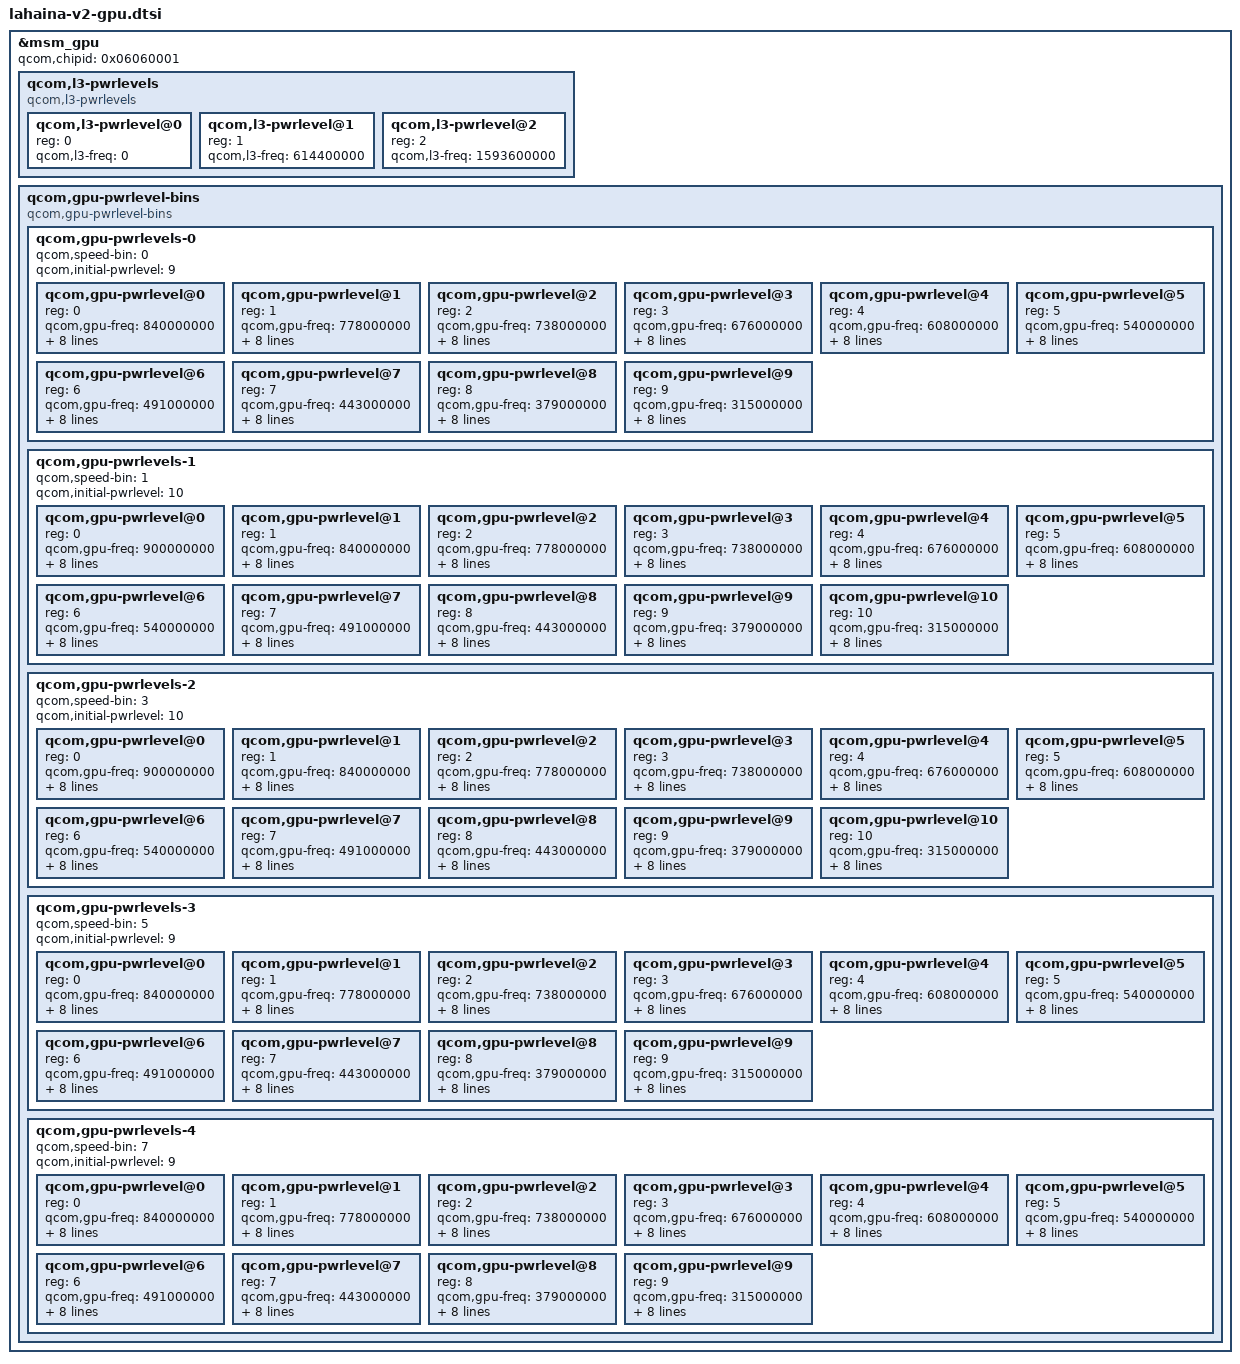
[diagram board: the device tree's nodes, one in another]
&msm_gpu {
	qcom,chipid = <0x06060001>;

	/delete-property/qcom,initial-pwrlevel;
	/delete-node/qcom,gpu-pwrlevels;

	qcom,l3-pwrlevels {
			#address-cells = <1>;
			#size-cells = <0>;

			compatible = "qcom,l3-pwrlevels";

			qcom,l3-pwrlevel@0 {
				reg = <0>;
				qcom,l3-freq = <0>;
			};

			qcom,l3-pwrlevel@1 {
				reg = <1>;
				qcom,l3-freq = <614400000>;
			};

			qcom,l3-pwrlevel@2 {
				reg = <2>;
				qcom,l3-freq = <1593600000>;
			};
		};

	/* Power levels bins */
	qcom,gpu-pwrlevel-bins {
		compatible="qcom,gpu-pwrlevel-bins";
		#address-cells = <1>;
		#size-cells = <0>;

		qcom,gpu-pwrlevels-0 {
			#address-cells = <1>;
			#size-cells = <0>;
			qcom,speed-bin = <0>;
			qcom,initial-pwrlevel = <9>;

			qcom,gpu-pwrlevel@0 {
				reg = <0>;
				qcom,gpu-freq = <840000000>;
				qcom,level = <RPMH_REGULATOR_LEVEL_TURBO_L1>;

				qcom,bus-freq-ddr7 = <11>;
				qcom,bus-min-ddr7 = <11>;
				qcom,bus-max-ddr7 = <11>;

				qcom,bus-freq-ddr8 = <11>;
				qcom,bus-min-ddr8 = <11>;
				qcom,bus-max-ddr8 = <11>;

				qcom,acd-level = <0x882a5ffd>;
			};

			qcom,gpu-pwrlevel@1 {
				reg = <1>;
				qcom,gpu-freq = <778000000>;
				qcom,level = <RPMH_REGULATOR_LEVEL_TURBO>;

				qcom,bus-freq-ddr7 = <11>;
				qcom,bus-min-ddr7 = <11>;
				qcom,bus-max-ddr7 = <11>;

				qcom,bus-freq-ddr8 = <11>;
				qcom,bus-min-ddr8 = <11>;
				qcom,bus-max-ddr8 = <11>;

				qcom,acd-level = <0xa82a5ffd>;
			};

			qcom,gpu-pwrlevel@2 {
				reg = <2>;
				qcom,gpu-freq = <738000000>;
				qcom,level = <RPMH_REGULATOR_LEVEL_NOM_L1>;

				qcom,bus-freq-ddr7 = <11>;
				qcom,bus-min-ddr7 = <11>;
				qcom,bus-max-ddr7 = <11>;

				qcom,bus-freq-ddr8 = <11>;
				qcom,bus-min-ddr8 = <11>;
				qcom,bus-max-ddr8 = <11>;

				qcom,acd-level = <0xa82a5ffd>;
			};

			qcom,gpu-pwrlevel@3 {
				reg = <3>;
				qcom,gpu-freq = <676000000>;
				qcom,level = <RPMH_REGULATOR_LEVEL_NOM>;

				qcom,bus-freq-ddr7 = <11>;
				qcom,bus-min-ddr7 = <11>;
				qcom,bus-max-ddr7 = <11>;

				qcom,bus-freq-ddr8 = <10>;
				qcom,bus-min-ddr8 = <10>;
				qcom,bus-max-ddr8 = <11>;

				qcom,acd-level = <0x882b5ffd>;
			};

			qcom,gpu-pwrlevel@4 {
				reg = <4>;
				qcom,gpu-freq = <608000000>;
				qcom,level = <RPMH_REGULATOR_LEVEL_SVS_L2>;

				qcom,bus-freq-ddr7 = <8>;
				qcom,bus-min-ddr7 = <7>;
				qcom,bus-max-ddr7 = <11>;

				qcom,bus-freq-ddr8 = <7>;
				qcom,bus-min-ddr8 = <7>;
				qcom,bus-max-ddr8 = <11>;

				qcom,acd-level = <0xa82b5ffd>;
			};

			qcom,gpu-pwrlevel@5 {
				reg = <5>;
				qcom,gpu-freq = <540000000>;
				qcom,level = <RPMH_REGULATOR_LEVEL_SVS_L1>;

				qcom,bus-freq-ddr7 = <8>;
				qcom,bus-min-ddr7 = <7>;
				qcom,bus-max-ddr7 = <10>;

				qcom,bus-freq-ddr8 = <7>;
				qcom,bus-min-ddr8 = <7>;
				qcom,bus-max-ddr8 = <9>;

				qcom,acd-level = <0xa82c5ffd>;
			};

			qcom,gpu-pwrlevel@6 {
				reg = <6>;
				qcom,gpu-freq = <491000000>;
				qcom,level = <RPMH_REGULATOR_LEVEL_SVS_L0>;

				qcom,bus-freq-ddr7 = <8>;
				qcom,bus-min-ddr7 = <6>;
				qcom,bus-max-ddr7 = <10>;

				qcom,bus-freq-ddr8 = <7>;
				qcom,bus-min-ddr8 = <5>;
				qcom,bus-max-ddr8 = <7>;

				qcom,acd-level = <0xa82c5ffd>;
			};

			qcom,gpu-pwrlevel@7 {
				reg = <7>;
				qcom,gpu-freq = <443000000>;
				qcom,level = <RPMH_REGULATOR_LEVEL_SVS>;

				qcom,bus-freq-ddr7 = <8>;
				qcom,bus-min-ddr7 = <6>;
				qcom,bus-max-ddr7 = <10>;

				qcom,bus-freq-ddr8 = <7>;
				qcom,bus-min-ddr8 = <5>;
				qcom,bus-max-ddr8 = <7>;

				qcom,acd-level = <0xa82d5ffd>;
			};

			qcom,gpu-pwrlevel@8 {
				reg = <8>;
				qcom,gpu-freq = <379000000>;
				qcom,level = <RPMH_REGULATOR_LEVEL_LOW_SVS_L1>;

				qcom,bus-freq-ddr7 = <8>;
				qcom,bus-min-ddr7 = <6>;
				qcom,bus-max-ddr7 = <10>;

				qcom,bus-freq-ddr8 = <6>;
				qcom,bus-min-ddr8 = <5>;
				qcom,bus-max-ddr8 = <7>;

				qcom,acd-level = <0x882e5ffd>;
			};

			qcom,gpu-pwrlevel@9 {
				reg = <9>;
				qcom,gpu-freq = <315000000>;
				qcom,level = <RPMH_REGULATOR_LEVEL_LOW_SVS>;

				qcom,bus-freq-ddr7 = <2>;
				qcom,bus-min-ddr7 = <2>;
				qcom,bus-max-ddr7 = <9>;

				qcom,bus-freq-ddr8 = <2>;
				qcom,bus-min-ddr8 = <2>;
				qcom,bus-max-ddr8 = <7>;

				qcom,acd-level = <0x882f5ffd>;
			};

		};

		qcom,gpu-pwrlevels-1 {
			#address-cells = <1>;
			#size-cells = <0>;
			qcom,speed-bin = <1>;
			qcom,initial-pwrlevel = <10>;

			qcom,gpu-pwrlevel@0 {
				reg = <0>;
				qcom,gpu-freq = <900000000>;
				qcom,level = <RPMH_REGULATOR_LEVEL_TURBO_L2>;

				qcom,bus-freq-ddr7 = <11>;
				qcom,bus-min-ddr7 = <11>;
				qcom,bus-max-ddr7 = <11>;

				qcom,bus-freq-ddr8 = <11>;
				qcom,bus-min-ddr8 = <11>;
				qcom,bus-max-ddr8 = <11>;

				qcom,acd-level = <0x882a5ffd>;
			};

			qcom,gpu-pwrlevel@1 {
				reg = <1>;
				qcom,gpu-freq = <840000000>;
				qcom,level = <RPMH_REGULATOR_LEVEL_TURBO_L1>;

				qcom,bus-freq-ddr7 = <11>;
				qcom,bus-min-ddr7 = <11>;
				qcom,bus-max-ddr7 = <11>;

				qcom,bus-freq-ddr8 = <11>;
				qcom,bus-min-ddr8 = <11>;
				qcom,bus-max-ddr8 = <11>;

				qcom,acd-level = <0x882a5ffd>;
			};

			qcom,gpu-pwrlevel@2 {
				reg = <2>;
				qcom,gpu-freq = <778000000>;
				qcom,level = <RPMH_REGULATOR_LEVEL_TURBO>;

				qcom,bus-freq-ddr7 = <11>;
				qcom,bus-min-ddr7 = <11>;
				qcom,bus-max-ddr7 = <11>;

				qcom,bus-freq-ddr8 = <11>;
				qcom,bus-min-ddr8 = <11>;
				qcom,bus-max-ddr8 = <11>;

				qcom,acd-level = <0xa82a5ffd>;
			};

			qcom,gpu-pwrlevel@3 {
				reg = <3>;
				qcom,gpu-freq = <738000000>;
				qcom,level = <RPMH_REGULATOR_LEVEL_NOM_L1>;

				qcom,bus-freq-ddr7 = <11>;
				qcom,bus-min-ddr7 = <11>;
				qcom,bus-max-ddr7 = <11>;

				qcom,bus-freq-ddr8 = <11>;
				qcom,bus-min-ddr8 = <11>;
				qcom,bus-max-ddr8 = <11>;

				qcom,acd-level = <0xa82a5ffd>;
			};

			qcom,gpu-pwrlevel@4 {
				reg = <4>;
				qcom,gpu-freq = <676000000>;
				qcom,level = <RPMH_REGULATOR_LEVEL_NOM>;

				qcom,bus-freq-ddr7 = <11>;
				qcom,bus-min-ddr7 = <11>;
				qcom,bus-max-ddr7 = <11>;

				qcom,bus-freq-ddr8 = <10>;
				qcom,bus-min-ddr8 = <10>;
				qcom,bus-max-ddr8 = <11>;

				qcom,acd-level = <0x882b5ffd>;
			};

			qcom,gpu-pwrlevel@5 {
				reg = <5>;
				qcom,gpu-freq = <608000000>;
				qcom,level = <RPMH_REGULATOR_LEVEL_SVS_L2>;

				qcom,bus-freq-ddr7 = <8>;
				qcom,bus-min-ddr7 = <7>;
				qcom,bus-max-ddr7 = <11>;

				qcom,bus-freq-ddr8 = <7>;
				qcom,bus-min-ddr8 = <7>;
				qcom,bus-max-ddr8 = <11>;

				qcom,acd-level = <0xa82b5ffd>;
			};

			qcom,gpu-pwrlevel@6 {
				reg = <6>;
				qcom,gpu-freq = <540000000>;
				qcom,level = <RPMH_REGULATOR_LEVEL_SVS_L1>;

				qcom,bus-freq-ddr7 = <8>;
				qcom,bus-min-ddr7 = <7>;
				qcom,bus-max-ddr7 = <10>;

				qcom,bus-freq-ddr8 = <7>;
				qcom,bus-min-ddr8 = <7>;
				qcom,bus-max-ddr8 = <9>;

				qcom,acd-level = <0xa82c5ffd>;
			};

			qcom,gpu-pwrlevel@7 {
				reg = <7>;
				qcom,gpu-freq = <491000000>;
				qcom,level = <RPMH_REGULATOR_LEVEL_SVS_L0>;

				qcom,bus-freq-ddr7 = <8>;
				qcom,bus-min-ddr7 = <6>;
				qcom,bus-max-ddr7 = <10>;

				qcom,bus-freq-ddr8 = <7>;
				qcom,bus-min-ddr8 = <5>;
				qcom,bus-max-ddr8 = <7>;

				qcom,acd-level = <0xa82c5ffd>;
			};

			qcom,gpu-pwrlevel@8 {
				reg = <8>;
				qcom,gpu-freq = <443000000>;
				qcom,level = <RPMH_REGULATOR_LEVEL_SVS>;

				qcom,bus-freq-ddr7 = <8>;
				qcom,bus-min-ddr7 = <6>;
				qcom,bus-max-ddr7 = <10>;

				qcom,bus-freq-ddr8 = <7>;
				qcom,bus-min-ddr8 = <5>;
				qcom,bus-max-ddr8 = <7>;

				qcom,acd-level = <0xa82d5ffd>;
			};

			qcom,gpu-pwrlevel@9 {
				reg = <9>;
				qcom,gpu-freq = <379000000>;
				qcom,level = <RPMH_REGULATOR_LEVEL_LOW_SVS_L1>;

				qcom,bus-freq-ddr7 = <8>;
				qcom,bus-min-ddr7 = <6>;
				qcom,bus-max-ddr7 = <10>;

				qcom,bus-freq-ddr8 = <6>;
				qcom,bus-min-ddr8 = <5>;
				qcom,bus-max-ddr8 = <7>;

				qcom,acd-level = <0x882e5ffd>;
			};

			qcom,gpu-pwrlevel@10 {
				reg = <10>;
				qcom,gpu-freq = <315000000>;
				qcom,level = <RPMH_REGULATOR_LEVEL_LOW_SVS>;

				qcom,bus-freq-ddr7 = <2>;
				qcom,bus-min-ddr7 = <2>;
				qcom,bus-max-ddr7 = <9>;

				qcom,bus-freq-ddr8 = <2>;
				qcom,bus-min-ddr8 = <2>;
				qcom,bus-max-ddr8 = <7>;

				qcom,acd-level = <0x882f5ffd>;
			};
		};

		qcom,gpu-pwrlevels-2 {
			#address-cells = <1>;
			#size-cells = <0>;
			qcom,speed-bin = <3>;
			qcom,initial-pwrlevel = <10>;

			qcom,gpu-pwrlevel@0 {
				reg = <0>;
				qcom,gpu-freq = <900000000>;
				qcom,level = <RPMH_REGULATOR_LEVEL_TURBO_L2>;

				qcom,bus-freq-ddr7 = <11>;
				qcom,bus-min-ddr7 = <11>;
				qcom,bus-max-ddr7 = <11>;

				qcom,bus-freq-ddr8 = <11>;
				qcom,bus-min-ddr8 = <11>;
				qcom,bus-max-ddr8 = <11>;

				qcom,acd-level = <0x882a5ffd>;
			};

			qcom,gpu-pwrlevel@1 {
				reg = <1>;
				qcom,gpu-freq = <840000000>;
				qcom,level = <RPMH_REGULATOR_LEVEL_TURBO_L1>;

				qcom,bus-freq-ddr7 = <11>;
				qcom,bus-min-ddr7 = <11>;
				qcom,bus-max-ddr7 = <11>;

				qcom,bus-freq-ddr8 = <11>;
				qcom,bus-min-ddr8 = <11>;
				qcom,bus-max-ddr8 = <11>;

				qcom,acd-level = <0x882a5ffd>;
			};

			qcom,gpu-pwrlevel@2 {
				reg = <2>;
				qcom,gpu-freq = <778000000>;
				qcom,level = <RPMH_REGULATOR_LEVEL_TURBO>;

				qcom,bus-freq-ddr7 = <11>;
				qcom,bus-min-ddr7 = <11>;
				qcom,bus-max-ddr7 = <11>;

				qcom,bus-freq-ddr8 = <11>;
				qcom,bus-min-ddr8 = <11>;
				qcom,bus-max-ddr8 = <11>;

				qcom,acd-level = <0xa82a5ffd>;
			};

			qcom,gpu-pwrlevel@3 {
				reg = <3>;
				qcom,gpu-freq = <738000000>;
				qcom,level = <RPMH_REGULATOR_LEVEL_NOM_L1>;

				qcom,bus-freq-ddr7 = <11>;
				qcom,bus-min-ddr7 = <11>;
				qcom,bus-max-ddr7 = <11>;

				qcom,bus-freq-ddr8 = <11>;
				qcom,bus-min-ddr8 = <11>;
				qcom,bus-max-ddr8 = <11>;

				qcom,acd-level = <0xa82a5ffd>;
			};

			qcom,gpu-pwrlevel@4 {
				reg = <4>;
				qcom,gpu-freq = <676000000>;
				qcom,level = <RPMH_REGULATOR_LEVEL_NOM>;

				qcom,bus-freq-ddr7 = <11>;
				qcom,bus-min-ddr7 = <11>;
				qcom,bus-max-ddr7 = <11>;

				qcom,bus-freq-ddr8 = <10>;
				qcom,bus-min-ddr8 = <10>;
				qcom,bus-max-ddr8 = <11>;

				qcom,acd-level = <0x882b5ffd>;
			};

			qcom,gpu-pwrlevel@5 {
				reg = <5>;
				qcom,gpu-freq = <608000000>;
				qcom,level = <RPMH_REGULATOR_LEVEL_SVS_L2>;

				qcom,bus-freq-ddr7 = <8>;
				qcom,bus-min-ddr7 = <7>;
				qcom,bus-max-ddr7 = <11>;

				qcom,bus-freq-ddr8 = <7>;
				qcom,bus-min-ddr8 = <7>;
				qcom,bus-max-ddr8 = <11>;

				qcom,acd-level = <0xa82b5ffd>;
			};

			qcom,gpu-pwrlevel@6 {
				reg = <6>;
				qcom,gpu-freq = <540000000>;
				qcom,level = <RPMH_REGULATOR_LEVEL_SVS_L1>;

				qcom,bus-freq-ddr7 = <8>;
				qcom,bus-min-ddr7 = <7>;
				qcom,bus-max-ddr7 = <10>;

				qcom,bus-freq-ddr8 = <7>;
				qcom,bus-min-ddr8 = <7>;
				qcom,bus-max-ddr8 = <9>;

				qcom,acd-level = <0xa82c5ffd>;
			};

			qcom,gpu-pwrlevel@7 {
				reg = <7>;
				qcom,gpu-freq = <491000000>;
				qcom,level = <RPMH_REGULATOR_LEVEL_SVS_L0>;

				qcom,bus-freq-ddr7 = <8>;
				qcom,bus-min-ddr7 = <6>;
				qcom,bus-max-ddr7 = <10>;

				qcom,bus-freq-ddr8 = <7>;
				qcom,bus-min-ddr8 = <5>;
				qcom,bus-max-ddr8 = <7>;

				qcom,acd-level = <0xa82c5ffd>;
			};

			qcom,gpu-pwrlevel@8 {
				reg = <8>;
				qcom,gpu-freq = <443000000>;
				qcom,level = <RPMH_REGULATOR_LEVEL_SVS>;

				qcom,bus-freq-ddr7 = <8>;
				qcom,bus-min-ddr7 = <6>;
				qcom,bus-max-ddr7 = <10>;

				qcom,bus-freq-ddr8 = <7>;
				qcom,bus-min-ddr8 = <5>;
				qcom,bus-max-ddr8 = <7>;

				qcom,acd-level = <0xa82d5ffd>;
			};

			qcom,gpu-pwrlevel@9 {
				reg = <9>;
				qcom,gpu-freq = <379000000>;
				qcom,level = <RPMH_REGULATOR_LEVEL_LOW_SVS_L1>;

				qcom,bus-freq-ddr7 = <8>;
				qcom,bus-min-ddr7 = <6>;
				qcom,bus-max-ddr7 = <10>;

				qcom,bus-freq-ddr8 = <6>;
				qcom,bus-min-ddr8 = <5>;
				qcom,bus-max-ddr8 = <7>;

				qcom,acd-level = <0x882e5ffd>;
			};

			qcom,gpu-pwrlevel@10 {
				reg = <10>;
				qcom,gpu-freq = <315000000>;
				qcom,level = <RPMH_REGULATOR_LEVEL_LOW_SVS>;

				qcom,bus-freq-ddr7 = <2>;
				qcom,bus-min-ddr7 = <2>;
				qcom,bus-max-ddr7 = <9>;

				qcom,bus-freq-ddr8 = <2>;
				qcom,bus-min-ddr8 = <2>;
				qcom,bus-max-ddr8 = <7>;

				qcom,acd-level = <0x882f5ffd>;
			};
		};

		qcom,gpu-pwrlevels-3 {
			#address-cells = <1>;
			#size-cells = <0>;
			qcom,speed-bin = <5>;
			qcom,initial-pwrlevel = <9>;

			qcom,gpu-pwrlevel@0 {
				reg = <0>;
				qcom,gpu-freq = <840000000>;
				qcom,level = <RPMH_REGULATOR_LEVEL_TURBO_L1>;

				qcom,bus-freq-ddr7 = <11>;
				qcom,bus-min-ddr7 = <11>;
				qcom,bus-max-ddr7 = <11>;

				qcom,bus-freq-ddr8 = <11>;
				qcom,bus-min-ddr8 = <11>;
				qcom,bus-max-ddr8 = <11>;

				qcom,acd-level = <0x882a5ffd>;
			};

			qcom,gpu-pwrlevel@1 {
				reg = <1>;
				qcom,gpu-freq = <778000000>;
				qcom,level = <RPMH_REGULATOR_LEVEL_TURBO>;

				qcom,bus-freq-ddr7 = <11>;
				qcom,bus-min-ddr7 = <11>;
				qcom,bus-max-ddr7 = <11>;

				qcom,bus-freq-ddr8 = <11>;
				qcom,bus-min-ddr8 = <11>;
				qcom,bus-max-ddr8 = <11>;

				qcom,acd-level = <0xa82a5ffd>;
			};

			qcom,gpu-pwrlevel@2 {
				reg = <2>;
				qcom,gpu-freq = <738000000>;
				qcom,level = <RPMH_REGULATOR_LEVEL_NOM_L1>;

				qcom,bus-freq-ddr7 = <11>;
				qcom,bus-min-ddr7 = <11>;
				qcom,bus-max-ddr7 = <11>;

				qcom,bus-freq-ddr8 = <11>;
				qcom,bus-min-ddr8 = <11>;
				qcom,bus-max-ddr8 = <11>;

				qcom,acd-level = <0xa82a5ffd>;
			};

			qcom,gpu-pwrlevel@3 {
				reg = <3>;
				qcom,gpu-freq = <676000000>;
				qcom,level = <RPMH_REGULATOR_LEVEL_NOM>;

				qcom,bus-freq-ddr7 = <11>;
				qcom,bus-min-ddr7 = <11>;
				qcom,bus-max-ddr7 = <11>;

				qcom,bus-freq-ddr8 = <10>;
				qcom,bus-min-ddr8 = <10>;
				qcom,bus-max-ddr8 = <11>;

				qcom,acd-level = <0x882b5ffd>;
			};

			qcom,gpu-pwrlevel@4 {
				reg = <4>;
				qcom,gpu-freq = <608000000>;
				qcom,level = <RPMH_REGULATOR_LEVEL_SVS_L2>;

				qcom,bus-freq-ddr7 = <8>;
				qcom,bus-min-ddr7 = <7>;
				qcom,bus-max-ddr7 = <11>;

				qcom,bus-freq-ddr8 = <7>;
				qcom,bus-min-ddr8 = <7>;
				qcom,bus-max-ddr8 = <11>;

				qcom,acd-level = <0xa82b5ffd>;
			};

			qcom,gpu-pwrlevel@5 {
				reg = <5>;
				qcom,gpu-freq = <540000000>;
				qcom,level = <RPMH_REGULATOR_LEVEL_SVS_L1>;

				qcom,bus-freq-ddr7 = <8>;
				qcom,bus-min-ddr7 = <7>;
				qcom,bus-max-ddr7 = <10>;

				qcom,bus-freq-ddr8 = <7>;
				qcom,bus-min-ddr8 = <7>;
				qcom,bus-max-ddr8 = <9>;

				qcom,acd-level = <0xa82c5ffd>;
			};

			qcom,gpu-pwrlevel@6 {
				reg = <6>;
				qcom,gpu-freq = <491000000>;
				qcom,level = <RPMH_REGULATOR_LEVEL_SVS_L0>;

				qcom,bus-freq-ddr7 = <8>;
				qcom,bus-min-ddr7 = <6>;
				qcom,bus-max-ddr7 = <10>;

				qcom,bus-freq-ddr8 = <7>;
				qcom,bus-min-ddr8 = <5>;
				qcom,bus-max-ddr8 = <7>;

				qcom,acd-level = <0xa82c5ffd>;
			};

			qcom,gpu-pwrlevel@7 {
				reg = <7>;
				qcom,gpu-freq = <443000000>;
				qcom,level = <RPMH_REGULATOR_LEVEL_SVS>;

				qcom,bus-freq-ddr7 = <8>;
				qcom,bus-min-ddr7 = <6>;
				qcom,bus-max-ddr7 = <10>;

				qcom,bus-freq-ddr8 = <7>;
				qcom,bus-min-ddr8 = <5>;
				qcom,bus-max-ddr8 = <7>;

				qcom,acd-level = <0xa82d5ffd>;
			};

			qcom,gpu-pwrlevel@8 {
				reg = <8>;
				qcom,gpu-freq = <379000000>;
				qcom,level = <RPMH_REGULATOR_LEVEL_LOW_SVS_L1>;

				qcom,bus-freq-ddr7 = <8>;
				qcom,bus-min-ddr7 = <6>;
				qcom,bus-max-ddr7 = <10>;

				qcom,bus-freq-ddr8 = <6>;
				qcom,bus-min-ddr8 = <5>;
				qcom,bus-max-ddr8 = <7>;

				qcom,acd-level = <0x882e5ffd>;
			};

			qcom,gpu-pwrlevel@9 {
				reg = <9>;
				qcom,gpu-freq = <315000000>;
				qcom,level = <RPMH_REGULATOR_LEVEL_LOW_SVS>;

				qcom,bus-freq-ddr7 = <2>;
				qcom,bus-min-ddr7 = <2>;
				qcom,bus-max-ddr7 = <9>;

				qcom,bus-freq-ddr8 = <2>;
				qcom,bus-min-ddr8 = <2>;
				qcom,bus-max-ddr8 = <7>;

				qcom,acd-level = <0x882f5ffd>;
			};
		};

		qcom,gpu-pwrlevels-4 {
			#address-cells = <1>;
			#size-cells = <0>;
			qcom,speed-bin = <7>;
			qcom,initial-pwrlevel = <9>;

			qcom,gpu-pwrlevel@0 {
				reg = <0>;
				qcom,gpu-freq = <840000000>;
				qcom,level = <RPMH_REGULATOR_LEVEL_TURBO_L1>;

				qcom,bus-freq-ddr7 = <11>;
				qcom,bus-min-ddr7 = <11>;
				qcom,bus-max-ddr7 = <11>;

				qcom,bus-freq-ddr8 = <11>;
				qcom,bus-min-ddr8 = <11>;
				qcom,bus-max-ddr8 = <11>;

				qcom,acd-level = <0x882a5ffd>;
			};

			qcom,gpu-pwrlevel@1 {
				reg = <1>;
				qcom,gpu-freq = <778000000>;
				qcom,level = <RPMH_REGULATOR_LEVEL_TURBO>;

				qcom,bus-freq-ddr7 = <11>;
				qcom,bus-min-ddr7 = <11>;
				qcom,bus-max-ddr7 = <11>;

				qcom,bus-freq-ddr8 = <11>;
				qcom,bus-min-ddr8 = <11>;
				qcom,bus-max-ddr8 = <11>;

				qcom,acd-level = <0xa82a5ffd>;
			};

			qcom,gpu-pwrlevel@2 {
				reg = <2>;
				qcom,gpu-freq = <738000000>;
				qcom,level = <RPMH_REGULATOR_LEVEL_NOM_L1>;

				qcom,bus-freq-ddr7 = <11>;
				qcom,bus-min-ddr7 = <11>;
				qcom,bus-max-ddr7 = <11>;

				qcom,bus-freq-ddr8 = <11>;
				qcom,bus-min-ddr8 = <11>;
				qcom,bus-max-ddr8 = <11>;

				qcom,acd-level = <0xa82a5ffd>;
			};

			qcom,gpu-pwrlevel@3 {
				reg = <3>;
				qcom,gpu-freq = <676000000>;
				qcom,level = <RPMH_REGULATOR_LEVEL_NOM>;

				qcom,bus-freq-ddr7 = <11>;
				qcom,bus-min-ddr7 = <11>;
				qcom,bus-max-ddr7 = <11>;

				qcom,bus-freq-ddr8 = <10>;
				qcom,bus-min-ddr8 = <10>;
				qcom,bus-max-ddr8 = <11>;

				qcom,acd-level = <0x882b5ffd>;
			};

			qcom,gpu-pwrlevel@4 {
				reg = <4>;
				qcom,gpu-freq = <608000000>;
				qcom,level = <RPMH_REGULATOR_LEVEL_SVS_L2>;

				qcom,bus-freq-ddr7 = <8>;
				qcom,bus-min-ddr7 = <7>;
				qcom,bus-max-ddr7 = <11>;

				qcom,bus-freq-ddr8 = <7>;
				qcom,bus-min-ddr8 = <7>;
				qcom,bus-max-ddr8 = <11>;

				qcom,acd-level = <0xa82b5ffd>;
			};

			qcom,gpu-pwrlevel@5 {
				reg = <5>;
				qcom,gpu-freq = <540000000>;
				qcom,level = <RPMH_REGULATOR_LEVEL_SVS_L1>;

				qcom,bus-freq-ddr7 = <8>;
				qcom,bus-min-ddr7 = <7>;
				qcom,bus-max-ddr7 = <10>;

				qcom,bus-freq-ddr8 = <7>;
				qcom,bus-min-ddr8 = <7>;
				qcom,bus-max-ddr8 = <9>;

				qcom,acd-level = <0xa82c5ffd>;
			};

			qcom,gpu-pwrlevel@6 {
				reg = <6>;
				qcom,gpu-freq = <491000000>;
				qcom,level = <RPMH_REGULATOR_LEVEL_SVS_L0>;

				qcom,bus-freq-ddr7 = <8>;
				qcom,bus-min-ddr7 = <6>;
				qcom,bus-max-ddr7 = <10>;

				qcom,bus-freq-ddr8 = <7>;
				qcom,bus-min-ddr8 = <5>;
				qcom,bus-max-ddr8 = <7>;

				qcom,acd-level = <0xa82c5ffd>;
			};

			qcom,gpu-pwrlevel@7 {
				reg = <7>;
				qcom,gpu-freq = <443000000>;
				qcom,level = <RPMH_REGULATOR_LEVEL_SVS>;

				qcom,bus-freq-ddr7 = <8>;
				qcom,bus-min-ddr7 = <6>;
				qcom,bus-max-ddr7 = <10>;

				qcom,bus-freq-ddr8 = <7>;
				qcom,bus-min-ddr8 = <5>;
				qcom,bus-max-ddr8 = <7>;

				qcom,acd-level = <0xa82d5ffd>;
			};

			qcom,gpu-pwrlevel@8 {
				reg = <8>;
				qcom,gpu-freq = <379000000>;
				qcom,level = <RPMH_REGULATOR_LEVEL_LOW_SVS_L1>;

				qcom,bus-freq-ddr7 = <8>;
				qcom,bus-min-ddr7 = <6>;
				qcom,bus-max-ddr7 = <10>;

				qcom,bus-freq-ddr8 = <6>;
				qcom,bus-min-ddr8 = <5>;
				qcom,bus-max-ddr8 = <7>;

				qcom,acd-level = <0x882e5ffd>;
			};

			qcom,gpu-pwrlevel@9 {
				reg = <9>;
				qcom,gpu-freq = <315000000>;
				qcom,level = <RPMH_REGULATOR_LEVEL_LOW_SVS>;

				qcom,bus-freq-ddr7 = <2>;
				qcom,bus-min-ddr7 = <2>;
				qcom,bus-max-ddr7 = <9>;

				qcom,bus-freq-ddr8 = <2>;
				qcom,bus-min-ddr8 = <2>;
				qcom,bus-max-ddr8 = <7>;

				qcom,acd-level = <0x882f5ffd>;
			};
		};
	};
};
